# ESP32-P4 register map
Vendor: ESPRESSIF SYSTEMS (SHANGHAI) CO., LTD.; Series: ESP32 P-Series; File version: 2
CPU: RV32IMAFC r0p0, little endian, no MPU, FPU, 0 interrupt priority bits
Address unit: 32 bits
Registers are 32-bit, read-write, reset 0x0 unless marked. A register's access mark holds for its fields unless they carry their own. Offsets are from the block's base; [hi:lo] are bit positions; {n}, {i} and the like mark numbered series.

## LP_I2C0 — Low-power I2C (Inter-Integrated Circuit) Controller 0
Base 0x50122000
0x00 SCL_LOW_PERIOD — Configures the low level width of the SCL Clock
  [8:0] SCL_LOW_PERIOD — Configures the low level width of the SCL Clock. Measurement unit: i2c_sclk.
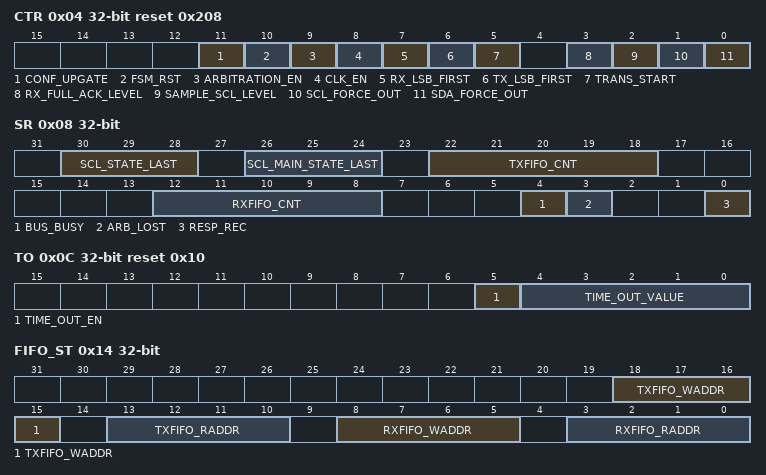
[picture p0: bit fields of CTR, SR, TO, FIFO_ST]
0x04 CTR access per field reset 0x208 — Transmission setting
  [11] CONF_UPGATE wo — Configures this bit for synchronization 0: No effect 1: Synchronize
  [10] FSM_RST wo — Configures to reset the SCL_FSM. 0: No effect 1: Reset
  [9] ARBITRATION_EN rw — Configures to enable I2C bus arbitration detection. 0: No effect 1: Enable
  [8] CLK_EN rw — Configures whether to gate clock signal for registers. 0: Force clock on for registers 1: Support clock only when registers are read or written to by software.
  [7] RX_LSB_FIRST rw — Configures to control the storage order for received data. 1: receive data from the least significant bit 0: receive data from the most significant bit.
  [6] TX_LSB_FIRST rw — Configures to control the sending order for data needing to be sent. 1: send data from the least significant bit, 0: send data from the most significant bit.
  [5] TRANS_START wo — Configures to start sending the data in txfifo for slave. 0: No effect 1: Start
  [3] RX_FULL_ACK_LEVEL rw — Configures the ACK value that needs to be sent by master when the rx_fifo_cnt has reached the threshold.
  [2] SAMPLE_SCL_LEVEL rw — Configures the sample mode for SDA. 1: Sample SDA data on the SCL low level. 0: Sample SDA data on the SCL high level.
  [1] SCL_FORCE_OUT rw — Configures the SCL output mode 1: Direct output, 0: Open drain output.
  [0] SDA_FORCE_OUT rw — Configures the SDA output mode 1: Direct output, 0: Open drain output.
0x08 SR ro — Describe I2C work status.
  [30:28] SCL_STATE_LAST — Represents the states of the state machine used to produce SCL. 0: Idle, 1: Start, 2: Negative edge, 3: Low, 4: Positive edge, 5: High, 6: Stop
  [26:24] SCL_MAIN_STATE_LAST — Represents the states of the I2C module state machine. 0: Idle, 1: Address shift, 2: ACK address, 3: Rx data, 4: Tx data, 5: Send ACK, 6: Wait ACK
  [22:18] TXFIFO_CNT — Represents the number of data bytes received in RAM.
  [12:8] RXFIFO_CNT — Represents the number of data bytes to be sent.
  [4] BUS_BUSY — Represents the I2C bus state. 1: The I2C bus is busy transferring data, 0: The I2C bus is in idle state.
  [3] ARB_LOST — Represents whether the I2C controller loses control of SCL line. 0: No arbitration lost 1: Arbitration lost
  [0] RESP_REC — Represents the received ACK value in master mode or slave mode. 0: ACK, 1: NACK.
0x0C TO reset 0x10 — Setting time out control for receiving data.
  [5] TIME_OUT_EN — Configures to enable time out control. 0: No effect 1: Enable
  [4:0] TIME_OUT_VALUE — Configures the timeout threshold period for SCL stucking at high or low level. The actual period is 2^(reg_time_out_value). Measurement unit: i2c_sclk.
0x14 FIFO_ST ro — FIFO status register.
  [18:15] TXFIFO_WADDR — Represents the offset address of APB bus writing to TXFIFO.
  [13:10] TXFIFO_RADDR — Represents the offset address of i2c module reading from TXFIFO.
  [8:5] RXFIFO_WADDR — Represents the offset address of i2c module receiving data and writing to RXFIFO.
  [3:0] RXFIFO_RADDR — Represents the offset address of the APB reading from RXFIFO
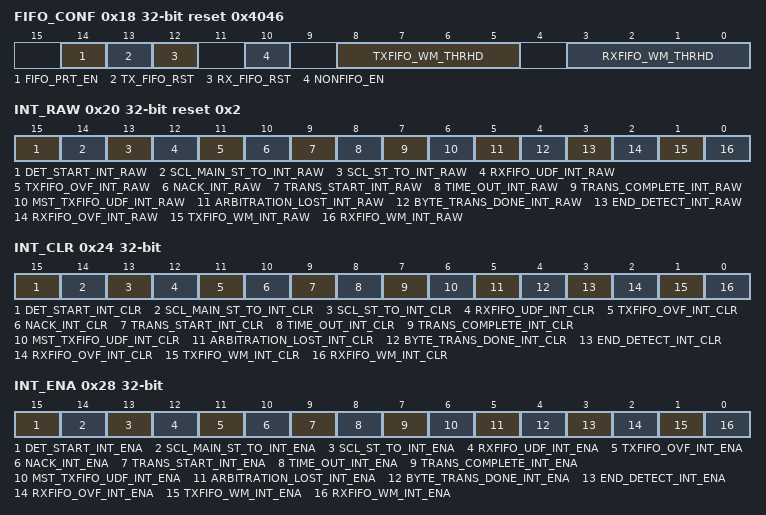
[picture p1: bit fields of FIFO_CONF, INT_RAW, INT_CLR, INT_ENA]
0x18 FIFO_CONF reset 0x4046 — FIFO configuration register.
  [14] FIFO_PRT_EN — Configures to enable FIFO pointer in non-fifo access mode. This bit controls the valid bits and the TX/RX FIFO overflow, underflow, full and empty interrupts. 0: No effect 1: Enable
  [13] TX_FIFO_RST — Configures to reset TXFIFO. 0: No effect 1: Reset
  [12] RX_FIFO_RST — Configures to reset RXFIFO. 0: No effect 1: Reset
  [10] NONFIFO_EN — Configures to enable APB nonfifo access.
  [8:5] TXFIFO_WM_THRHD — Configures the water mark threshold of TXFIFO in nonfifo access mode. When reg_reg_fifo_prt_en is 1 and tx FIFO counter is smaller than reg_txfifo_wm_thrhd[3:0], reg_txfifo_wm_int_raw bit will be valid.
  [3:0] RXFIFO_WM_THRHD — Configures the water mark threshold of RXFIFO in nonfifo access mode. When reg_reg_fifo_prt_en is 1 and rx FIFO counter is bigger than reg_rxfifo_wm_thrhd[3:0], reg_rxfifo_wm_int_raw bit will be valid.
0x1C DATA ro — Rx FIFO read data.
  [7:0] FIFO_RDATA — Represents the value of RXFIFO read data.
0x20 INT_RAW ro reset 0x2 — Raw interrupt status
  [15] DET_START_INT_RAW — The raw interrupt status of I2C_DET_START_INT interrupt.
  [14] SCL_MAIN_ST_TO_INT_RAW — The raw interrupt status of I2C_SCL_MAIN_ST_TO_INT interrupt.
  [13] SCL_ST_TO_INT_RAW — The raw interrupt status of I2C_SCL_ST_TO_INT interrupt.
  [12] RXFIFO_UDF_INT_RAW — The raw interrupt status of I2C_RXFIFO_UDF_INT interrupt.
  [11] TXFIFO_OVF_INT_RAW — The raw interrupt status of I2C_TXFIFO_OVF_INT interrupt.
  [10] NACK_INT_RAW — The raw interrupt status of I2C_SLAVE_STRETCH_INT interrupt.
  [9] TRANS_START_INT_RAW — The raw interrupt status of the I2C_TRANS_START_INT interrupt.
  [8] TIME_OUT_INT_RAW — The raw interrupt status of the I2C_TIME_OUT_INT interrupt.
  [7] TRANS_COMPLETE_INT_RAW — The raw interrupt status of the I2C_TRANS_COMPLETE_INT interrupt.
  [6] MST_TXFIFO_UDF_INT_RAW — The raw interrupt status of I2C_TRANS_COMPLETE_INT interrupt.
  [5] ARBITRATION_LOST_INT_RAW — The raw interrupt status of the I2C_ARBITRATION_LOST_INT interrupt.
  [4] BYTE_TRANS_DONE_INT_RAW — The raw interrupt status of the I2C_END_DETECT_INT interrupt.
  [3] END_DETECT_INT_RAW — The raw interrupt status of the I2C_END_DETECT_INT interrupt.
  [2] RXFIFO_OVF_INT_RAW — The raw interrupt status of I2C_RXFIFO_OVF_INT interrupt.
  [1] TXFIFO_WM_INT_RAW — The raw interrupt status of I2C_TXFIFO_WM_INT interrupt.
  [0] RXFIFO_WM_INT_RAW — The raw interrupt status of I2C_RXFIFO_WM_INT interrupt.
0x24 INT_CLR wo — Interrupt clear bits
  [15] DET_START_INT_CLR — Write 1 to clear I2C_DET_START_INT interrupt.
  [14] SCL_MAIN_ST_TO_INT_CLR — Write 1 to clear I2C_SCL_MAIN_ST_TO_INT interrupt.
  [13] SCL_ST_TO_INT_CLR — Write 1 to clear I2C_SCL_ST_TO_INT interrupt.
  [12] RXFIFO_UDF_INT_CLR — Write 1 to clear I2C_RXFIFO_UDF_INT interrupt.
  [11] TXFIFO_OVF_INT_CLR — Write 1 to clear I2C_TXFIFO_OVF_INT interrupt.
  [10] NACK_INT_CLR — Write 1 to clear I2C_SLAVE_STRETCH_INT interrupt.
  [9] TRANS_START_INT_CLR — Write 1 to clear the I2C_TRANS_START_INT interrupt.
  [8] TIME_OUT_INT_CLR — Write 1 to clear the I2C_TIME_OUT_INT interrupt.
  [7] TRANS_COMPLETE_INT_CLR — Write 1 to clear the I2C_TRANS_COMPLETE_INT interrupt.
  [6] MST_TXFIFO_UDF_INT_CLR — Write 1 to clear I2C_TRANS_COMPLETE_INT interrupt.
  [5] ARBITRATION_LOST_INT_CLR — Write 1 to clear the I2C_ARBITRATION_LOST_INT interrupt.
  [4] BYTE_TRANS_DONE_INT_CLR — Write 1 to clear the I2C_END_DETECT_INT interrupt.
  [3] END_DETECT_INT_CLR — Write 1 to clear the I2C_END_DETECT_INT interrupt.
  [2] RXFIFO_OVF_INT_CLR — Write 1 to clear I2C_RXFIFO_OVF_INT interrupt.
  [1] TXFIFO_WM_INT_CLR — Write 1 to clear I2C_TXFIFO_WM_INT interrupt.
  [0] RXFIFO_WM_INT_CLR — Write 1 to clear I2C_RXFIFO_WM_INT interrupt.
0x28 INT_ENA — Interrupt enable bits
  [15] DET_START_INT_ENA — Write 1 to anable I2C_DET_START_INT interrupt.
  [14] SCL_MAIN_ST_TO_INT_ENA — Write 1 to anable I2C_SCL_MAIN_ST_TO_INT interrupt.
  [13] SCL_ST_TO_INT_ENA — Write 1 to anable I2C_SCL_ST_TO_INT interrupt.
  [12] RXFIFO_UDF_INT_ENA — Write 1 to anable I2C_RXFIFO_UDF_INT interrupt.
  [11] TXFIFO_OVF_INT_ENA — Write 1 to anable I2C_TXFIFO_OVF_INT interrupt.
  [10] NACK_INT_ENA — Write 1 to anable I2C_SLAVE_STRETCH_INT interrupt.
  [9] TRANS_START_INT_ENA — Write 1 to anable the I2C_TRANS_START_INT interrupt.
  [8] TIME_OUT_INT_ENA — Write 1 to anable the I2C_TIME_OUT_INT interrupt.
  [7] TRANS_COMPLETE_INT_ENA — Write 1 to anable the I2C_TRANS_COMPLETE_INT interrupt.
  [6] MST_TXFIFO_UDF_INT_ENA — Write 1 to anable I2C_TRANS_COMPLETE_INT interrupt.
  [5] ARBITRATION_LOST_INT_ENA — Write 1 to anable the I2C_ARBITRATION_LOST_INT interrupt.
  [4] BYTE_TRANS_DONE_INT_ENA — Write 1 to anable the I2C_END_DETECT_INT interrupt.
  [3] END_DETECT_INT_ENA — Write 1 to anable the I2C_END_DETECT_INT interrupt.
  [2] RXFIFO_OVF_INT_ENA — Write 1 to anable I2C_RXFIFO_OVF_INT interrupt.
  [1] TXFIFO_WM_INT_ENA — Write 1 to anable I2C_TXFIFO_WM_INT interrupt.
  [0] RXFIFO_WM_INT_ENA — Write 1 to anable I2C_RXFIFO_WM_INT interrupt.
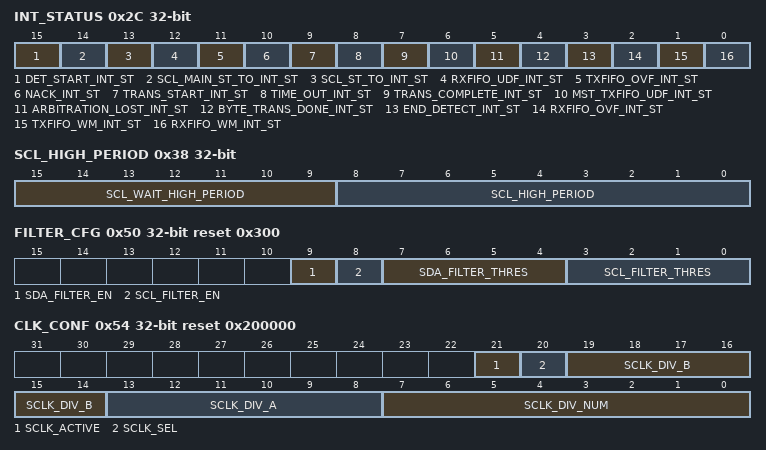
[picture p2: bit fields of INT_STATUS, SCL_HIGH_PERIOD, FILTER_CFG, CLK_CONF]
0x2C INT_STATUS ro — Status of captured I2C communication events
  [15] DET_START_INT_ST — The masked interrupt status status of I2C_DET_START_INT interrupt.
  [14] SCL_MAIN_ST_TO_INT_ST — The masked interrupt status status of I2C_SCL_MAIN_ST_TO_INT interrupt.
  [13] SCL_ST_TO_INT_ST — The masked interrupt status status of I2C_SCL_ST_TO_INT interrupt.
  [12] RXFIFO_UDF_INT_ST — The masked interrupt status status of I2C_RXFIFO_UDF_INT interrupt.
  [11] TXFIFO_OVF_INT_ST — The masked interrupt status status of I2C_TXFIFO_OVF_INT interrupt.
  [10] NACK_INT_ST — The masked interrupt status status of I2C_SLAVE_STRETCH_INT interrupt.
  [9] TRANS_START_INT_ST — The masked interrupt status status of the I2C_TRANS_START_INT interrupt.
  [8] TIME_OUT_INT_ST — The masked interrupt status status of the I2C_TIME_OUT_INT interrupt.
  [7] TRANS_COMPLETE_INT_ST — The masked interrupt status status of the I2C_TRANS_COMPLETE_INT interrupt.
  [6] MST_TXFIFO_UDF_INT_ST — The masked interrupt status status of I2C_TRANS_COMPLETE_INT interrupt.
  [5] ARBITRATION_LOST_INT_ST — The masked interrupt status status of the I2C_ARBITRATION_LOST_INT interrupt.
  [4] BYTE_TRANS_DONE_INT_ST — The masked interrupt status status of the I2C_END_DETECT_INT interrupt.
  [3] END_DETECT_INT_ST — The masked interrupt status status of the I2C_END_DETECT_INT interrupt.
  [2] RXFIFO_OVF_INT_ST — The masked interrupt status status of I2C_RXFIFO_OVF_INT interrupt.
  [1] TXFIFO_WM_INT_ST — The masked interrupt status status of I2C_TXFIFO_WM_INT interrupt.
  [0] RXFIFO_WM_INT_ST — The masked interrupt status status of I2C_RXFIFO_WM_INT interrupt.
0x30 SDA_HOLD — Configures the hold time after a negative SCL edge.
  [8:0] TIME — Configures the time to hold the data after the falling edge of SCL. Measurement unit: i2c_sclk
0x34 SDA_SAMPLE — Configures the sample time after a positive SCL edge.
  [8:0] TIME — Configures the sample time after a positive SCL edge. Measurement unit: i2c_sclk
0x38 SCL_HIGH_PERIOD — Configures the high level width of SCL
  [15:9] SCL_WAIT_HIGH_PERIOD — Configures the SCL_FSM's waiting period for SCL high level in master mode. Measurement unit: i2c_sclk
  [8:0] SCL_HIGH_PERIOD — Configures for how long SCL remains high in master mode. Measurement unit: i2c_sclk
0x40 SCL_START_HOLD reset 0x8 — Configures the delay between the SDA and SCL negative edge for a start condition
  [8:0] TIME — Configures the time between the falling edge of SDA and the falling edge of SCL for a START condition. Measurement unit: i2c_sclk.
0x44 SCL_RSTART_SETUP reset 0x8 — Configures the delay between the positive edge of SCL and the negative edge of SDA
  [8:0] TIME — Configures the time between the positive edge of SCL and the negative edge of SDA for a RESTART condition. Measurement unit: i2c_sclk
0x48 SCL_STOP_HOLD reset 0x8 — Configures the delay after the SCL clock edge for a stop condition
  [8:0] TIME — Configures the delay after the STOP condition. Measurement unit: i2c_sclk
0x4C SCL_STOP_SETUP reset 0x8 — Configures the delay between the SDA and SCL positive edge for a stop condition
  [8:0] TIME — Configures the time between the rising edge of SCL and the rising edge of SDA. Measurement unit: i2c_sclk
0x50 FILTER_CFG reset 0x300 — SCL and SDA filter configuration register
  [9] SDA_FILTER_EN — Configures to enable the filter function for SDA.
  [8] SCL_FILTER_EN — Configures to enable the filter function for SCL.
  [7:4] SDA_FILTER_THRES — Configures the threshold pulse width to be filtered on SDA. When a pulse on the SDA input has smaller width than this register value, the I2C controller will ignore that pulse. Measurement unit: i2c_sclk
  [3:0] SCL_FILTER_THRES — Configures the threshold pulse width to be filtered on SCL. When a pulse on the SCL input has smaller width than this register value, the I2C controller will ignore that pulse. Measurement unit: i2c_sclk
0x54 CLK_CONF reset 0x200000 — I2C CLK configuration register
  [21] SCLK_ACTIVE — The clock switch for i2c module
  [20] SCLK_SEL — The clock selection for i2c module:0-XTAL,1-CLK_8MHz.
  [19:14] SCLK_DIV_B — the denominator of the fractional part of the fractional divisor for i2c module
  [13:8] SCLK_DIV_A — the numerator of the fractional part of the fractional divisor for i2c module
  [7:0] SCLK_DIV_NUM — the integral part of the fractional divisor for i2c module
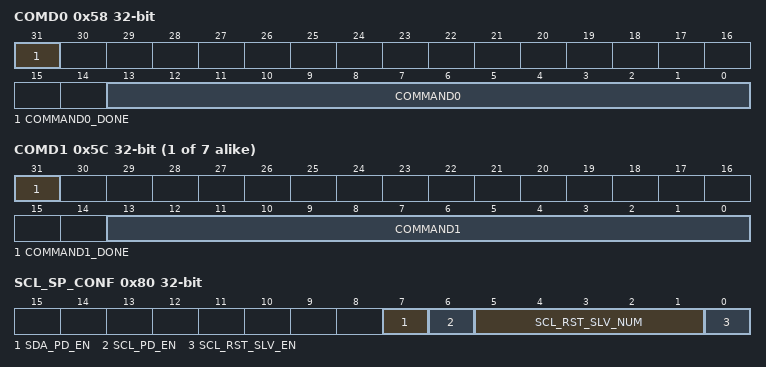
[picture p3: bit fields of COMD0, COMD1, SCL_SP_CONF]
0x58 COMD0 — I2C command register 0
  [31] COMMAND0_DONE — Represents whether command 0 is done in I2C Master mode. 0: Not done 1: Done
  [13:0] COMMAND0 — Configures command 0. It consists of three parts: op_code is the command, 0: RSTART, 1: WRITE, 2: READ, 3: STOP, 4: END. Byte_num represents the number of bytes that need to be sent or received. ack_check_en, ack_exp and ack are used to control the ACK bit. See I2C cmd structure for more information.
{0x58+4i} COMD{i} (i=1..7) — I2C command register {i}
  [31] COMMAND{i}_DONE — Represents whether command {i} is done in I2C Master mode. 0: Not done 1: Done
  [13:0] COMMAND{i} — Configures command {i}. See details in I2C_CMD0_REG[13:0].
0x78 SCL_ST_TIME_OUT reset 0x10 — SCL status time out register
  [4:0] SCL_ST_TO_I2C — Configures the threshold value of SCL_FSM state unchanged period. It should be no more than 23. Measurement unit: i2c_sclk
0x7C SCL_MAIN_ST_TIME_OUT reset 0x10 — SCL main status time out register
  [4:0] SCL_MAIN_ST_TO_I2C — Configures the threshold value of SCL_MAIN_FSM state unchanged period.nIt should be no more than 23. Measurement unit: i2c_sclk
0x80 SCL_SP_CONF — Power configuration register
  [7] SDA_PD_EN — Configures to power down the I2C output SCL line. 0: Not power down. 1: Power down. Valid only when reg_scl_force_out is 1.
  [6] SCL_PD_EN — Configure the pulses of SCL generated in I2C master mode. Valid when reg_scl_rst_slv_en is 1. Measurement unit: i2c_sclk
  [5:1] SCL_RST_SLV_NUM — Configures to send out SCL pulses when I2C master is IDLE. The number of pulses equals to reg_scl_rst_slv_num[4:0].
  [0] SCL_RST_SLV_EN — When I2C master is IDLE, set this bit to send out SCL pulses. The number of pulses equals to reg_scl_rst_slv_num[4:0].
0xF8 DATE reset 0x2201143 — Version register
  [31:0] DATE — Version control register.
0x100 TXFIFO_START_ADDR ro — I2C TXFIFO base address register
  [31:0] TXFIFO_START_ADDR — Represents the I2C txfifo first address.
0x180 RXFIFO_START_ADDR ro — I2C RXFIFO base address register
  [31:0] RXFIFO_START_ADDR — Represents the I2C rxfifo first address.
